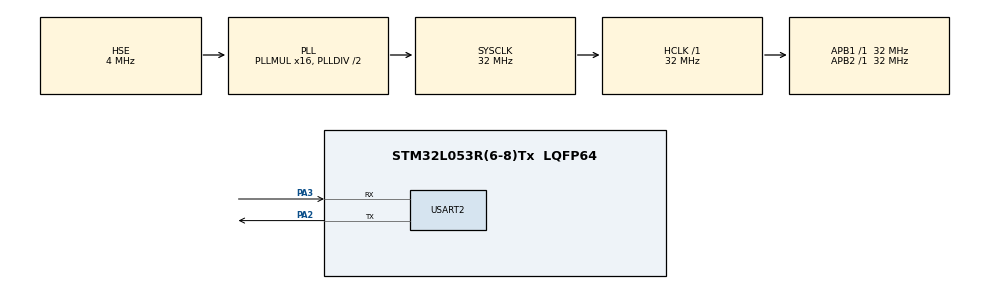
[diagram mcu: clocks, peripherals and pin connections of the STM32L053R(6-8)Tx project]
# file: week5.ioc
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Mcu.Family=STM32L0
Mcu.Name=STM32L053R(6-8)Tx
Mcu.Package=LQFP64
PA13.Mode=Serial_Wire
PA13.Signal=SYS_SWDIO
PA14.Mode=Serial_Wire
PA14.Signal=SYS_SWCLK
PA2.Mode=Asynchronous
PA2.Signal=USART2_TX
PA3.Mode=Asynchronous
PA3.Signal=USART2_RX
PH0-OSC_IN.Mode=HSE-External-Oscillator
PH0-OSC_IN.Signal=RCC_OSC_IN
PH1-OSC_OUT.Mode=HSE-External-Oscillator
PH1-OSC_OUT.Signal=RCC_OSC_OUT
ProjectManager.HeapSize=0x200
ProjectManager.StackSize=0x400
ProjectManager.TargetToolchain=MDK-ARM V5.27
RCC.AHBFreq_Value=32000000
RCC.APB1Freq_Value=32000000
RCC.APB1TimFreq_Value=32000000
RCC.APB2Freq_Value=32000000
RCC.APB2TimFreq_Value=32000000
RCC.HCLKFreq_Value=32000000
RCC.HSE_VALUE=4000000
RCC.HSI16_VALUE=16000000
RCC.HSI48_VALUE=48000000
RCC.HSI_VALUE=16000000
RCC.LSE_VALUE=32768
RCC.MSI_VALUE=2097000
RCC.PLLMUL=RCC_PLLMUL_16
RCC.PLLSourceVirtual=RCC_PLLSOURCE_HSE
RCC.SYSCLKFreq_VALUE=32000000
RCC.SYSCLKSource=RCC_SYSCLKSOURCE_PLLCLK
RCC.VCOOutputFreq_Value=64000000
USART2.VirtualMode-Asynchronous=VM_ASYNC
board=custom

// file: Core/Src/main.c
/* USER CODE BEGIN Header */
/**
  ******************************************************************************
  * @file           : main.c
  * @brief          : Main program body
  ******************************************************************************
  * @attention
  *
  * <h2><center>&copy; Copyright (c) 2021 STMicroelectronics.
  * All rights reserved.</center></h2>
  *
  * This software component is licensed by ST under BSD 3-Clause license,
  * the "License"; You may not use this file except in compliance with the
  * License. You may obtain a copy of the License at:
  *                        opensource.org/licenses/BSD-3-Clause
  *
  ******************************************************************************
  */
/* USER CODE END Header */
#include "main.h"
#include "usart.h"
#include "gpio.h"

/* USER CODE BEGIN Includes */
#include <stdio.h>
/* USER CODE END Includes */

void SystemClock_Config(void);

/* USER CODE BEGIN 0 */
int fputc(int ch, FILE *f) {
  uint8_t temp[1] = {ch};
  HAL_UART_Transmit(&huart2, temp, 1, 2);
  return ch;
}
/* USER CODE END 0 */

int main(void)
{

  /* MCU Configuration--------------------------------------------------------*/

  /* Reset of all peripherals, Initializes the Flash interface and the Systick. */
  HAL_Init();

  /* Configure the system clock */
  SystemClock_Config();

  /* Initialize all configured peripherals */
  MX_GPIO_Init();
  MX_USART2_UART_Init();

  /* Infinite loop */
  /* USER CODE BEGIN WHILE */
  while (1)
  {
    printf("Hello STM32\r\n");
    HAL_Delay(1000);
    /* USER CODE END WHILE */

  }
}

void SystemClock_Config(void)
{
  RCC_OscInitTypeDef RCC_OscInitStruct = {0};
  RCC_ClkInitTypeDef RCC_ClkInitStruct = {0};
  RCC_PeriphCLKInitTypeDef PeriphClkInit = {0};

  /** Configure the main internal regulator output voltage
  */
  __HAL_PWR_VOLTAGESCALING_CONFIG(PWR_REGULATOR_VOLTAGE_SCALE1);
  /** Initializes the RCC Oscillators according to the specified parameters
  * in the RCC_OscInitTypeDef structure.
  */
  RCC_OscInitStruct.OscillatorType = RCC_OSCILLATORTYPE_HSE;
  RCC_OscInitStruct.HSEState = RCC_HSE_ON;
  RCC_OscInitStruct.PLL.PLLState = RCC_PLL_ON;
  RCC_OscInitStruct.PLL.PLLSource = RCC_PLLSOURCE_HSE;
  RCC_OscInitStruct.PLL.PLLMUL = RCC_PLLMUL_16;
  RCC_OscInitStruct.PLL.PLLDIV = RCC_PLLDIV_2;
  if (HAL_RCC_OscConfig(&RCC_OscInitStruct) != HAL_OK)
  {
    Error_Handler();
  }
  /** Initializes the CPU, AHB and APB buses clocks
  */
  RCC_ClkInitStruct.ClockType = RCC_CLOCKTYPE_HCLK|RCC_CLOCKTYPE_SYSCLK
                              |RCC_CLOCKTYPE_PCLK1|RCC_CLOCKTYPE_PCLK2;
  RCC_ClkInitStruct.SYSCLKSource = RCC_SYSCLKSOURCE_PLLCLK;
  RCC_ClkInitStruct.AHBCLKDivider = RCC_SYSCLK_DIV1;
  RCC_ClkInitStruct.APB1CLKDivider = RCC_HCLK_DIV1;
  RCC_ClkInitStruct.APB2CLKDivider = RCC_HCLK_DIV1;

  if (HAL_RCC_ClockConfig(&RCC_ClkInitStruct, FLASH_LATENCY_1) != HAL_OK)
  {
    Error_Handler();
  }
  PeriphClkInit.PeriphClockSelection = RCC_PERIPHCLK_USART2;
  PeriphClkInit.Usart2ClockSelection = RCC_USART2CLKSOURCE_PCLK1;
  if (HAL_RCCEx_PeriphCLKConfig(&PeriphClkInit) != HAL_OK)
  {
    Error_Handler();
  }
}

void Error_Handler(void)
{
  __disable_irq();
  while (1)
  {
  }
}

/************************ (C) COPYRIGHT STMicroelectronics *****END OF FILE****/
